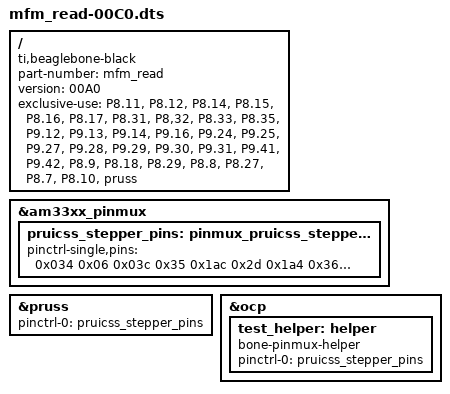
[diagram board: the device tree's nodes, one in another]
/dts-v1/;
/plugin/;

/ {
    compatible = "ti,beaglebone-black", "ti,beaglebone-green";

    /* identification */
    part-number = "mfm_read";

    /* version */
    version = "00A0";

    /* state the resources this cape uses or prepare to get winged! */
    exclusive-use =
        // MFM0_IN
        "P8.11",
        // MFM1_IN
        "P8.12",
        // Sel3
        "P8.14",
        // MFM_data
        "P8.15",
        // Sel1
        "P8.16",
        // Sel4
        "P8.17",
        // Head2,
        "P8.31",
        // Head3
        "P8,32",
         // Head1
        "P8.33",
         // Head0
        "P8.35",
        // EMU_EN
        "P9.12",
        // Recovery
        "P9.13",
        // MFM_READ_en
        "P9.14",
        // Write fault
        "P9.16",
        // Sel2
        "P9.24",
        // Step
        "P9.25",
        // Index
        "P9.27",
        // Track0
        "P9.28",
        // Selected
        "P9.29",
        // Seek_done
        "P9.30",
        // Write
        "P9.31",
        // DIR_IN
        "P9.41",
        // Ready
        "P9.42",
        // Expansion pins for external stepper use
        // ERR
        "P8.9",
        // EN
        "P8.18",
        // MODE0
        "P8.29",
        // MODE1
        "P8.8",
        // Mode2
        "P8.27",
        // Mode3
        "P8.7",
        // STBY
        "P8.10",
        /* Hardware IP cores in use */
        "pruss";

    fragment@0 {
        target = <&am33xx_pinmux>;
        __overlay__ {
            pruicss_stepper_pins: pinmux_pruicss_stepper_pins{
                pinctrl-single,pins = <
                     // All inputs pullup
                     // All outputs fast pullup disabled
                     // These go to PRU0
                    0x034 0x06 // OUT P8_11 = pr1_pru0_pru_30_15
                    0x03c 0x35 // IN/OUT  P8_15 = pr1_ecap0
                    0x1ac 0x2d // OUT P9_25 = pr1_pru0_pru_30_7
                    0x1a4 0x36 // IN  P9_27 = pr1_pru0_pru_31_5
                    0x194 0x36 // IN  P9_29 = pr1_pru0_pru_31_1
                    0x198 0x36 // IN  P9_30 = pr1_pru0_pru_31_2
                    0x1a8 0x2d // OUT P9_41 = pr1_pru0_pru_30_6
                    0x1a0 0x36 // IN  P9_42.1 = pr1_pru0_pru_31_4

                     // These are GPIO
                    0x030 0x0f // OUT  P8_12 = gpio1_12
                    0x028 0x0f // OUT  P8_14 = gpio0_26
                    0x038 0x0f // OUT  P8_16 = gpio1_14
                    0x02c 0x0f // OUT  P8_17 = gpio0_27
                    0x0d8 0x0f // OUT  P8_31 = gpio0_10
                    0x0dc 0x0f // OUT  P8_32 = gpio0_11
                    0x0d4 0x0f // OUT  P8_33 = gpio0_09
                    0x0d0 0x0f // OUT  P8_35 = gpio0_08
                    0x078 0x0f // OUT  P9_12 = gpio1_28
                    0x074 0x0f // OUT  P9_13 = gpio0_31
                    0x048 0x0f // OUT  P9_14 = gpio1_18
                    0x04c 0x3f // IN   P9_16 = gpio0_05
                    0x184 0x0f // OUT  P9_24 = gpio0_15
                    0x19c 0x3f // IN   P9_28 = gpio3_17
                    //Only used for write, make GPIO for read
                    0x190 0x07 // OUT P9_31 = gpio3_14

                    // Rev C&D Stepper GPIO
                    0x09c 0x27 // IN   P8_09 = gpio2_06, pulldown ERR
                    0x08c 0x0f // OUT  P8_18 = gpio2_01 EN
                    0x0e4 0x0f // OUT  P8_29 = gpio2_23 MODE0
                    0x094 0x0f // OUT  P8_08 = gpio2_03 MODE1
                    0x0e0 0x0f // OUT  P8_27 = gpio2_22 MODE2
                    0x090 0x0f // OUT  P8_07 = gpio2_02 MODE3
                    0x098 0x0f // OUT  P8_10 = gpio2_04 STBY
                >;
            };

        };
    };

    fragment@1{
        target = <&pruss>;
        __overlay__{
            status = "okay";
            pinctrl-names = "default";
            pinctrl-0       = <&pruicss_stepper_pins>;

        };
    };
    fragment@2 {
        target = <&ocp>;
        __overlay__ {
            test_helper: helper {
                compatible = "bone-pinmux-helper";
                pinctrl-names = "default";
                pinctrl-0 = <&pruicss_stepper_pins>;
                status = "okay";
            };
        };
   };
};
